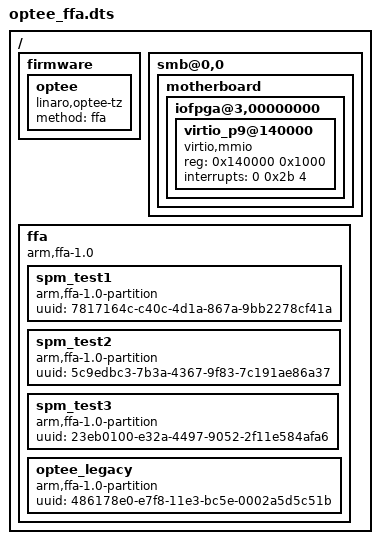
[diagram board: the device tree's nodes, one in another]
#include "fvp-base-gicv3-psci-1t.dts"

/ {
	firmware {
		optee {
			compatible = "linaro,optee-tz";
			method = "ffa";
		};
	};

	smb@0,0 {
		motherboard {
			iofpga@3,00000000 {
				virtio_p9@140000 {
					compatible = "virtio,mmio";
					reg = <0x140000 0x1000>;
					interrupts = <0 0x2b 4>;
				};
			};
		};
	};

	ffa {
		compatible = "arm,ffa-1.0";
		spm_test1 {
			compatible = "arm,ffa-1.0-partition";
			uuid = "7817164c-c40c-4d1a-867a-9bb2278cf41a";
		};
		spm_test2 {
			compatible = "arm,ffa-1.0-partition";
			uuid = "5c9edbc3-7b3a-4367-9f83-7c191ae86a37";
		};
		spm_test3 {
			compatible = "arm,ffa-1.0-partition";
			uuid = "23eb0100-e32a-4497-9052-2f11e584afa6";
		};

		optee_legacy {
			compatible = "arm,ffa-1.0-partition";
			uuid = "486178e0-e7f8-11e3-bc5e-0002a5d5c51b";
		};
	};
};
